# GPIO2 register map
Vendor: Texas Instruments
Peripheral module from a debugger description file (folder omap4430).
Registers are 32-bit, read-write, reset 0x0 unless marked. A register's access mark holds for its fields unless they carry their own. Offsets are as the file gives them; lines under a group give offsets from that group; [hi:lo] are bit positions; {n}, {i} and the like mark numbered series; 'fields as' and 'values as' point back to an identical list; <NAME> marks a mode.

## GPIO2
0x00 GPIO_REVISION ro reset not defined — IP revision identifier (X.Y.R)
  [31:0] REVISION — IP revision
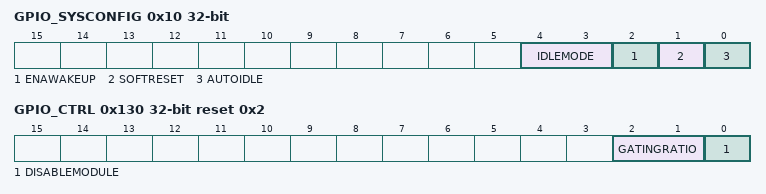
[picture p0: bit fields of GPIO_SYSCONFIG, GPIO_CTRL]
0x10 GPIO_SYSCONFIG access per field — System configuration register
  [4:3] IDLEMODE rw — 0x0: Force-idle: An idle request is acknowledged unconditionally.
    1=No-idle: An idle request is never acknowledged; 2=Smart-idle: The acknowledgment to an idle request is given based on the internal activity (see 4.1.2); 3=Smart-idle wakeup
  [2] ENAWAKEUP rw — Wake-up control
    0=Wake-up generation is disabled; 1=Wake-up capability is enabled upon expected transition on input GPIO pin
  [1] SOFTRESET rw — Software reset. Set this bit to 1 to trigger a module reset. The bit is automatically reset by the hardware. During reads, it always returns 0.
    0=Normal mode; 1=The module is reset
  [0] AUTOIDLE rw — OCP clock gating control.
    0=Internal Interface OCP clock is free-running; 1=Automatic internal OCP clock gating, based on the OCP interface activity
0x24 GPIO_IRQSTATUS_RAW_0 — Per-event raw interrupt status vector (corresponding to first line of interrupt)
  [31:0] INTLINE — Status raw for interrupt line
0x28 GPIO_IRQSTATUS_RAW_1 — Per-event raw interrupt status vector (corresponding to second line of interrupt)
  [31:0] INTLINE — Status raw for interrupt line
0x2C GPIO_IRQSTATUS_0 — Per-event interrupt status vector (enabled) (corresponding to first line of interrupt)
  [31:0] INTLINE — Status for interrupt line
0x30 GPIO_IRQSTATUS_1 — Per-event enabled interrupt status vector (corresponding to second line of interrupt)
  [31:0] INTLINE — Status for interrupt line
0x34 GPIO_IRQSTATUS_SET_0 — Per-event interrupt enable set vector (corresponding to first line of interrupt)
  [31:0] INTLINE — Status set for interrupt line
0x38 GPIO_IRQSTATUS_SET_1 — Per-event enable set interrupt vector (corresponding to second line of interrupt)
  [31:0] INTLINE — Status set for interrupt line
0x3C GPIO_IRQSTATUS_CLR_0 — Per-event interrupt enable clear vector (corresponding to first line of interrupt)
  [31:0] INTLINE — Status clear for interrupt line
0x40 GPIO_IRQSTATUS_CLR_1 — Per-event enable clear interrupt vector (corresponding to second line of interrupt)
  [31:0] INTLINE — Status clear for interrupt line
0x44 GPIO_IRQWAKEN_0 — Per-event wake-up enable set vector (corresponding to first line of interrupt)
  [31:0] INTLINE — Wakeup set for interrupt line
    0=Wakeup disable; 1=Wakeup enable
0x48 GPIO_IRQWAKEN_1 — Per-event wake-up enable set vector (corresponding to second line of interrupt)
  fields as GPIO_IRQWAKEN_0
0x114 GPIO_SYSSTATUS ro — System status register
  [0] RESETDONE
    0=RESETDONE_0_r (Internal reset is on-going.); 1=RESETDONE_1_r (Reset completed)
0x120 GPIO_WAKEUPENABLE — Wake-up enable register (legacy) for first line of interrupt
  [31:0] INTLINE — Wake-up enable for interrupt lineCaution:This register is kept for backward software compatibility. Use and instead. . Caution: A wake-up event can be enabled using a legacy register as well as the new one, but it must be disabled only through the register that enabled it. .
    0=Wake-up generation is disabled; 1=Wake-up generation is enabled
0x130 GPIO_CTRL access per field reset 0x2 — GPIO control register
  [2:1] GATINGRATIO rw — Clock gating ratio for event detection
    0=N = 1; 1=N = 2; 2=N = 4; 3=N = 8
  [0] DISABLEMODULE rw
    0=Module is enabled, clocks are not gated; 1=Module is disabled, internal clocks are gated
0x134 GPIO_OE reset 0xFFFFFFFF — Output enable register. 0: Output enabled ; 1: Output disabled
  [31:0] OUTPUTEN — Output enable
    0=Output enabled; 1=Output disabled
0x138 GPIO_DATAIN ro — Data input register (with sampled input data)
  [31:0] DATAIN — Sampled input data
0x13C GPIO_DATAOUT — Data output register (data to set on output pins).
  [31:0] DATAOUT — Data to set on output pins
0x140 GPIO_LEVELDETECT0 — Detect low-level register. 0: Low-level detection disabled; 1: Low-level detection enabled
  [31:0] LEVELDETECT0 — Low-level detection
    0=Low-level detection disabled; 1=Low-level detection enabled
0x144 GPIO_LEVELDETECT1 — Detect high-level register
  [31:0] LEVELDETECT1
    0=High-level detection disabled; 1=High-level detection enabled
0x148 GPIO_RISINGDETECT — Detect rising edge register
  [31:0] RISINGDETECT
    0=Rising edge detection disabled; 1=Rising edge detection enabled
0x14C GPIO_FALLINGDETECT — Detect falling edge register
  [31:0] FALLINGDETECT
    0=Falling edge detection disabled; 1=Falling edge detection enabled
0x150 GPIO_DEBOUNCENABLE — Debouncing enable register
  [31:0] DEBOUNCEENABLE
    0=No debouncing; 1=Debouncing activated
0x154 GPIO_DEBOUNCINGTIME access per field — Debouncing value register
  [7:0] DEBOUNCETIME rw — 8-bit values specifying the debouncing time in 31 µs steps
0x180 GPIO_CLEARWKUPENA — Clear wake-up-enable register – legacy register
  [31:0] INTLINE — This register is kept for backward software compatibility. Use GPIO_IRQWAKEN_0 and GPIO_IRQWAKEN_1 instead.Caution: A wake-up event can be enabled using a legacy register as well as the new one, but it must be disabled only through the register that enabled it. .
    0=No effect; 1=Clear the corresponding bit in the wake-up-enable register
0x184 GPIO_SETWKUENA — Set wake-up-enable register – legacy register
  [31:0] INTLINE — This register is kept for backward software compatibility. Use GPIO_IRQWAKEN_0 and GPIO_IRQWAKEN_1 instead.Caution: A wake-up event can be enabled using a legacy register as well as the new one, but it must be disabled only through the register that enabled it. .
    0=No effect; 1=Set the corresponding bit in the wake-up-enable register
0x190 GPIO_CLEARDATAOUT — Clear data output register
  [31:0] INTLINE
    0=No effect; 1=Clear the corresponding bit in the data output register
0x194 GPIO_SETDATAOUT — Set data output register
  [31:0] INTLINE
    0=No effect; 1=Set the corresponding bit in the data output register
